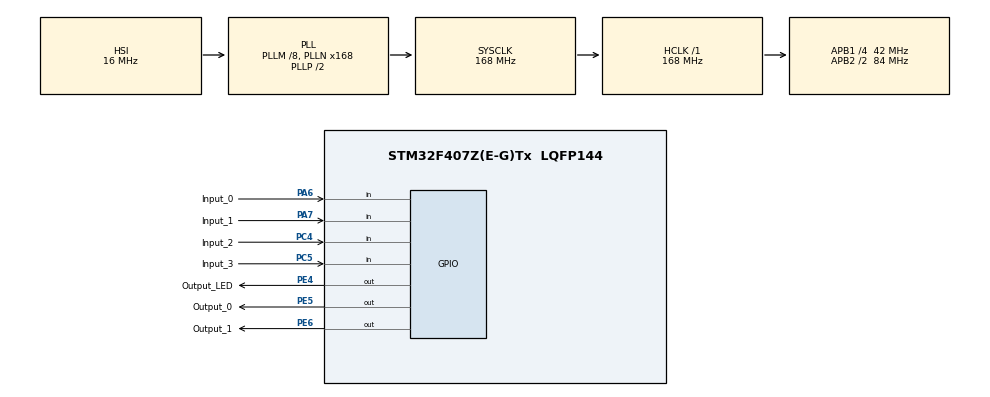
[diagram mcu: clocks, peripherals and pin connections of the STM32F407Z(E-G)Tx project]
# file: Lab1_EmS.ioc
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Mcu.Family=STM32F4
Mcu.Name=STM32F407Z(E-G)Tx
Mcu.Package=LQFP144
NVIC.PriorityGroup=NVIC_PRIORITYGROUP_4
PA13.Mode=Serial_Wire
PA13.Signal=SYS_JTMS-SWDIO
PA14.Mode=Serial_Wire
PA14.Signal=SYS_JTCK-SWCLK
PA6.GPIO_Label=Input_0
PA6.Signal=GPIO_Input
PA7.GPIO_Label=Input_1
PA7.Signal=GPIO_Input
PC4.GPIO_Label=Input_2
PC4.Signal=GPIO_Input
PC5.GPIO_Label=Input_3
PC5.Signal=GPIO_Input
PE4.GPIO_Label=Output_LED
PE4.Signal=GPIO_Output
PE5.GPIO_Label=Output_0
PE5.Signal=GPIO_Output
PE6.GPIO_Label=Output_1
PE6.Signal=GPIO_Output
PH0-OSC_IN.Mode=HSE-External-Oscillator
PH0-OSC_IN.Signal=RCC_OSC_IN
PH1-OSC_OUT.Mode=HSE-External-Oscillator
PH1-OSC_OUT.Signal=RCC_OSC_OUT
ProjectManager.HeapSize=0x200
ProjectManager.StackSize=0x400
ProjectManager.TargetToolchain=STM32CubeIDE
RCC.48MHZClocksFreq_Value=84000000
RCC.AHBFreq_Value=168000000
RCC.APB1CLKDivider=RCC_HCLK_DIV4
RCC.APB1Freq_Value=42000000
RCC.APB1TimFreq_Value=84000000
RCC.APB2CLKDivider=RCC_HCLK_DIV2
RCC.APB2Freq_Value=84000000
RCC.APB2TimFreq_Value=168000000
RCC.CortexFreq_Value=168000000
RCC.HCLKFreq_Value=168000000
RCC.HSE_VALUE=8000000
RCC.HSI_VALUE=16000000
RCC.LSE_VALUE=32768
RCC.PLLM=8
RCC.PLLN=168
RCC.SYSCLKFreq_VALUE=168000000
RCC.SYSCLKSource=RCC_SYSCLKSOURCE_PLLCLK
RCC.VCOOutputFreq_Value=336000000
board=custom

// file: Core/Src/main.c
/* USER CODE BEGIN Header */
/**
  ******************************************************************************
  * @file           : main.c
  * @brief          : Main program body
  ******************************************************************************
  * @attention
  *
  * <h2><center>&copy; Copyright (c) 2024 STMicroelectronics.
  * All rights reserved.</center></h2>
  *
  * This software component is licensed by ST under BSD 3-Clause license,
  * the "License"; You may not use this file except in compliance with the
  * License. You may obtain a copy of the License at:
  *                        opensource.org/licenses/BSD-3-Clause
  *
  ******************************************************************************
  */
/* USER CODE END Header */
#include "main.h"

void SystemClock_Config(void);
static void MX_GPIO_Init(void);

void traffic_light_control(void)

{
    uint32_t start_time = HAL_GetTick();  // Get the initial tick count
    uint32_t delay_time = 5000;           // Start with 5 seconds for Red
    uint8_t state = 0;                    // 0 = Red, 1 = Green, 2 = Yellow

    // Initial state: Red ON, Green and Yellow OFF
    HAL_GPIO_WritePin(Output_LED_GPIO_Port, Output_LED_Pin, 1);    // Red ON (0 = ON)
    HAL_GPIO_WritePin(Output_0_GPIO_Port, Output_0_Pin, 0);// Yellow OFF (1 = OFF)
    HAL_GPIO_WritePin(Output_1_GPIO_Port, Output_1_Pin, 0);  // Green OFF (1 = OFF)

    while (1)
    {
        // Check if the delay time has passed
        if (HAL_GetTick() - start_time >= delay_time)
        {
            // Transition the traffic lights between Red, Green, and Yellow
            switch (state)
            {
                case 0:  // Red to Green
                    HAL_GPIO_WritePin(Output_LED_GPIO_Port, Output_LED_Pin, 0);    // Red OFF
                    HAL_GPIO_WritePin(Output_0_GPIO_Port, Output_0_Pin, 0);  // yellow off
                    HAL_GPIO_WritePin(Output_1_GPIO_Port, Output_1_Pin, 1);  // Green ON
                    delay_time = 3000;  // Green for 3 seconds
                    state = 1;
                    break;

                case 1:  // Green to Yellow
                    HAL_GPIO_WritePin(Output_LED_GPIO_Port, Output_LED_Pin, 0);    // Red OFF
                    HAL_GPIO_WritePin(Output_0_GPIO_Port, Output_0_Pin, 1); // Yellow ON
                    HAL_GPIO_WritePin(Output_1_GPIO_Port, Output_1_Pin, 0);   // Green OFF
                    delay_time = 1000;  // Yellow for 1 second
                    state = 2;
                    break;

                case 2:  // Yellow to Red
                    HAL_GPIO_WritePin(Output_1_GPIO_Port, Output_1_Pin, 0);   // Green OFF
                    HAL_GPIO_WritePin(Output_0_GPIO_Port, Output_0_Pin, 0);  // Yellow OFF
                    HAL_GPIO_WritePin(Output_LED_GPIO_Port, Output_LED_Pin, 1);   // Red ON
                    delay_time = 5000;  // Red for 5 seconds
                    state = 0;
                    break;
            }

            // Reset the start time to the current time
            start_time = HAL_GetTick();
        }

    }
}

void toggle_gpio_delay(void)
{
    uint8_t gpio_state = 0;  // Initial state is GPIO OFF (LED OFF)
    uint32_t delay_time = 4000;  // Start with 4 seconds delay for LED OFF

    // Initial LED OFF
    HAL_GPIO_WritePin(Output_LED_GPIO_Port, Output_LED_Pin, 0);  // LED OFF (LOW)

    while (1)
    {
        // Toggle LED state
        gpio_state = !gpio_state;

        // Write the new state to the LED
        HAL_GPIO_WritePin(Output_LED_GPIO_Port, Output_LED_Pin, gpio_state ? 0 : 1);

        // Delay for either 2 or 4 seconds depending on the state
        HAL_Delay(delay_time);  // This is the only HAL_Delay()

        // After toggling, change the delay time
        delay_time = (gpio_state) ? 2000 : 4000;
    }
}

void toggle_gpio(void)
{
    uint32_t start_time = HAL_GetTick();  // Get the initial tick count
    uint32_t delay_time = 4000;           // Start with 4 seconds delay
    uint8_t gpio_state = 0;               // Initial state is GPIO HIGH (LED ON)

    HAL_GPIO_WritePin(Output_LED_GPIO_Port, Output_LED_Pin, 0);  // Set LED to ON

    while (1)
    {
        // Check if the delay time has passed
        if (HAL_GetTick() - start_time >= delay_time)
        {
            // Toggle LED state
            gpio_state = !gpio_state;

            // Write the new state to the LED
            HAL_GPIO_WritePin(Output_LED_GPIO_Port, Output_LED_Pin, gpio_state ? 1 : 0);

            delay_time = gpio_state ? 2000 : 4000;

            // Reset the start time to the current time
            start_time = HAL_GetTick();
        }

        // Other code can run here without blocking due to HAL_Delay
    }
}

void toogle_gpio_bai1(void){
	while (1){
	    HAL_GPIO_WritePin(Output_LED_GPIO_Port, Output_LED_Pin, 1);    // Red ON
	    HAL_Delay(2000);
	    HAL_GPIO_WritePin(Output_LED_GPIO_Port, Output_LED_Pin, 0);    // Red off
	    HAL_Delay(4000);
	}
}

int main(void)
{

  /* MCU Configuration--------------------------------------------------------*/

  /* Reset of all peripherals, Initializes the Flash interface and the Systick. */
  HAL_Init();

  /* Configure the system clock */
  SystemClock_Config();

  /* Initialize all configured peripherals */
  MX_GPIO_Init();

  /* Infinite loop */
  /* USER CODE BEGIN WHILE */

//  toggle_gpio();
  traffic_light_control();
//  toogle_gpio_bai1();
  while (1)
  {
    /* USER CODE END WHILE */

  }
}

void SystemClock_Config(void)
{
  RCC_OscInitTypeDef RCC_OscInitStruct = {0};
  RCC_ClkInitTypeDef RCC_ClkInitStruct = {0};

  /** Configure the main internal regulator output voltage
  */
  __HAL_RCC_PWR_CLK_ENABLE();
  __HAL_PWR_VOLTAGESCALING_CONFIG(PWR_REGULATOR_VOLTAGE_SCALE1);
  /** Initializes the RCC Oscillators according to the specified parameters
  * in the RCC_OscInitTypeDef structure.
  */
  RCC_OscInitStruct.OscillatorType = RCC_OSCILLATORTYPE_HSI;
  RCC_OscInitStruct.HSIState = RCC_HSI_ON;
  RCC_OscInitStruct.HSICalibrationValue = RCC_HSICALIBRATION_DEFAULT;
  RCC_OscInitStruct.PLL.PLLState = RCC_PLL_ON;
  RCC_OscInitStruct.PLL.PLLSource = RCC_PLLSOURCE_HSI;
  RCC_OscInitStruct.PLL.PLLM = 8;
  RCC_OscInitStruct.PLL.PLLN = 168;
  RCC_OscInitStruct.PLL.PLLP = RCC_PLLP_DIV2;
  RCC_OscInitStruct.PLL.PLLQ = 4;
  if (HAL_RCC_OscConfig(&RCC_OscInitStruct) != HAL_OK)
  {
    Error_Handler();
  }
  /** Initializes the CPU, AHB and APB buses clocks
  */
  RCC_ClkInitStruct.ClockType = RCC_CLOCKTYPE_HCLK|RCC_CLOCKTYPE_SYSCLK
                              |RCC_CLOCKTYPE_PCLK1|RCC_CLOCKTYPE_PCLK2;
  RCC_ClkInitStruct.SYSCLKSource = RCC_SYSCLKSOURCE_PLLCLK;
  RCC_ClkInitStruct.AHBCLKDivider = RCC_SYSCLK_DIV1;
  RCC_ClkInitStruct.APB1CLKDivider = RCC_HCLK_DIV4;
  RCC_ClkInitStruct.APB2CLKDivider = RCC_HCLK_DIV2;

  if (HAL_RCC_ClockConfig(&RCC_ClkInitStruct, FLASH_LATENCY_5) != HAL_OK)
  {
    Error_Handler();
  }
}

static void MX_GPIO_Init(void)
{
  GPIO_InitTypeDef GPIO_InitStruct = {0};

  /* GPIO Ports Clock Enable */
  __HAL_RCC_GPIOE_CLK_ENABLE();
  __HAL_RCC_GPIOH_CLK_ENABLE();
  __HAL_RCC_GPIOA_CLK_ENABLE();
  __HAL_RCC_GPIOC_CLK_ENABLE();

  /*Configure GPIO pin Output Level */
  HAL_GPIO_WritePin(GPIOE, Output_LED_Pin|Output_0_Pin|Output_1_Pin, GPIO_PIN_RESET);

  /*Configure GPIO pins : Output_LED_Pin Output_0_Pin Output_1_Pin */
  GPIO_InitStruct.Pin = Output_LED_Pin|Output_0_Pin|Output_1_Pin;
  GPIO_InitStruct.Mode = GPIO_MODE_OUTPUT_PP;
  GPIO_InitStruct.Pull = GPIO_NOPULL;
  GPIO_InitStruct.Speed = GPIO_SPEED_FREQ_LOW;
  HAL_GPIO_Init(GPIOE, &GPIO_InitStruct);

  /*Configure GPIO pins : Input_0_Pin Input_1_Pin */
  GPIO_InitStruct.Pin = Input_0_Pin|Input_1_Pin;
  GPIO_InitStruct.Mode = GPIO_MODE_INPUT;
  GPIO_InitStruct.Pull = GPIO_NOPULL;
  HAL_GPIO_Init(GPIOA, &GPIO_InitStruct);

  /*Configure GPIO pins : Input_2_Pin Input_3_Pin */
  GPIO_InitStruct.Pin = Input_2_Pin|Input_3_Pin;
  GPIO_InitStruct.Mode = GPIO_MODE_INPUT;
  GPIO_InitStruct.Pull = GPIO_NOPULL;
  HAL_GPIO_Init(GPIOC, &GPIO_InitStruct);

}

void Error_Handler(void)
{
  __disable_irq();
  while (1)
  {
  }
}

/************************ (C) COPYRIGHT STMicroelectronics *****END OF FILE****/
